VERSION ""

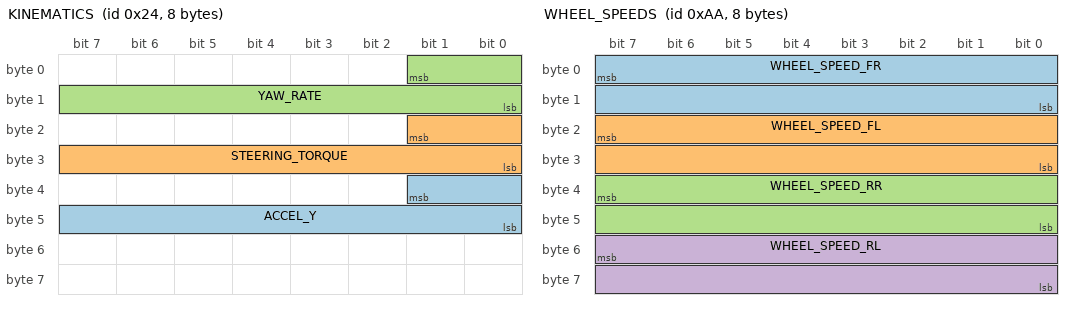
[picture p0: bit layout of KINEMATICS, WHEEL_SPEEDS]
BO_ 36 KINEMATICS: 8 XXX
 SG_ ACCEL_Y : 33|10@0+ (1,-512) [0|65535] "" XXX
 SG_ STEERING_TORQUE : 17|10@0+ (1,-512) [0|65535] "" XXX
 SG_ YAW_RATE : 1|10@0+ (1,-512) [0|65535] "" XXX

BO_ 166 BRAKE: 8 XXX
 SG_ BRAKE_AMOUNT : 7|8@0+ (1,0) [0|255] "" XXX
 SG_ BRAKE_PEDAL : 23|8@0+ (1,0) [0|255] "" XXX

BO_ 170 WHEEL_SPEEDS: 8 XXX
 SG_ WHEEL_SPEED_FR : 7|16@0+ (0.0062,-67.67) [0|250] "mph" XXX
 SG_ WHEEL_SPEED_FL : 23|16@0+ (0.0062,-67.67) [0|250] "mph" XXX
 SG_ WHEEL_SPEED_RR : 39|16@0+ (0.0062,-67.67) [0|250] "mph" XXX
 SG_ WHEEL_SPEED_RL : 55|16@0+ (0.0062,-67.67) [0|250] "mph" XXX

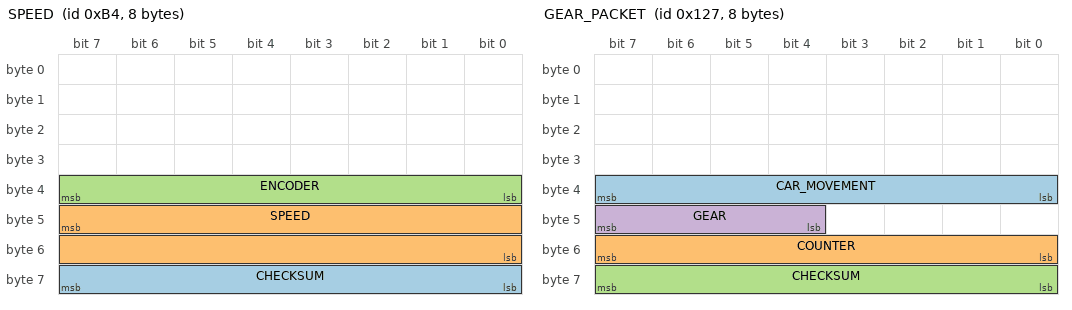
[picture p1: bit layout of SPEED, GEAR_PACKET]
BO_ 180 SPEED: 8 XXX
 SG_ CHECKSUM : 63|8@0+ (1,0) [0|255] "" XXX
 SG_ SPEED : 47|16@0+ (0.0062,0) [0|115] "mph" XXX
 SG_ ENCODER : 39|8@0+ (1,0) [0|255] "" XXX

BO_ 295 GEAR_PACKET: 8 XXX
 SG_ CAR_MOVEMENT : 39|8@0- (1,0) [0|255] "" XXX
 SG_ COUNTER : 55|8@0+ (1,0) [0|255] "" XXX
 SG_ CHECKSUM : 63|8@0+ (1,0) [0|255] "" XXX
 SG_ GEAR : 47|4@0+ (1,0) [0|15] "" XXX

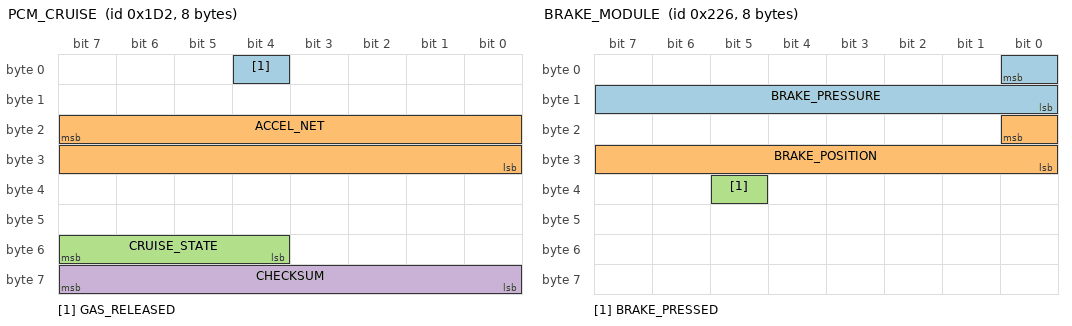
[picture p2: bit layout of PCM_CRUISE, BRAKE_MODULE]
BO_ 466 PCM_CRUISE: 8 XXX
 SG_ GAS_RELEASED : 4|1@0+ (1,0) [0|1] "" XXX
 SG_ ACCEL_NET : 23|16@0- (0.001,0) [-20|20] "m/s2" XXX
 SG_ CRUISE_STATE : 55|4@0+ (1,0) [0|15] "" XXX
 SG_ CHECKSUM : 63|8@0+ (1,0) [0|255] "" XXX

BO_ 550 BRAKE_MODULE: 8 XXX
 SG_ BRAKE_PRESSURE : 0|9@0+ (1,0) [0|511] "" XXX
 SG_ BRAKE_POSITION : 16|9@0+ (1,0) [0|511] "" XXX
 SG_ BRAKE_PRESSED : 37|1@0+ (1,0) [0|1] "" XXX

BO_ 552 ACCELEROMETER: 8 XXX
 SG_ ACCEL_Z : 22|15@0- (1,0) [0|32767] "" XXX
 SG_ ACCEL_X : 6|15@0- (0.001,0) [-20|20] "m/s2" XXX

BO_ 560 BRAKE_MODULE2: 8 XXX
 SG_ BRAKE_LIGHTS : 26|1@0+ (1,0) [0|1] "" XXX

BO_ 581 GAS_PEDAL: 8 XXX
 SG_ GAS_PEDAL : 23|8@0+ (0.005,0) [0|1] "" XXX

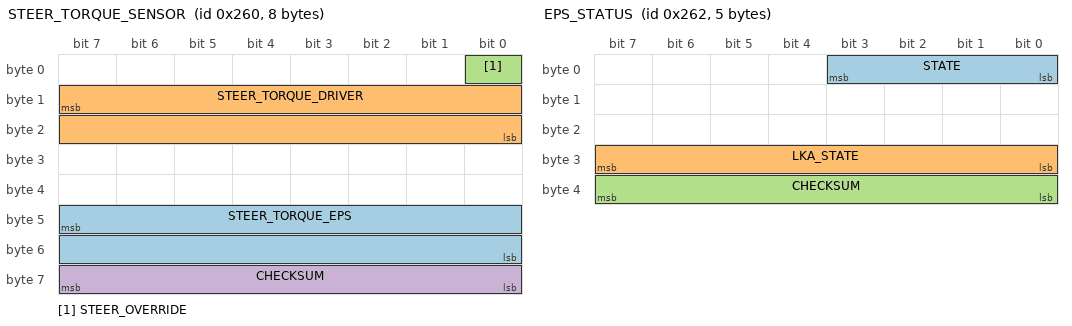
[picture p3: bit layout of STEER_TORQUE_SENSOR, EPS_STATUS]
BO_ 608 STEER_TORQUE_SENSOR: 8 XXX
 SG_ STEER_TORQUE_EPS : 47|16@0- (0.66,0) [-20000|20000] "" XXX
 SG_ STEER_TORQUE_DRIVER : 15|16@0- (1,0) [-32768|32767] "" XXX
 SG_ STEER_OVERRIDE : 0|1@0+ (1,0) [0|1] "" XXX
 SG_ CHECKSUM : 63|8@0+ (1,0) [0|255] "" XXX

BO_ 610 EPS_STATUS: 5 EPS
 SG_ STATE : 3|4@0+ (1,0) [0|15] "" XXX
 SG_ LKA_STATE : 31|8@0+ (1,0) [0|255] "" XXX
 SG_ CHECKSUM : 39|8@0+ (1,0) [0|255] "" XXX

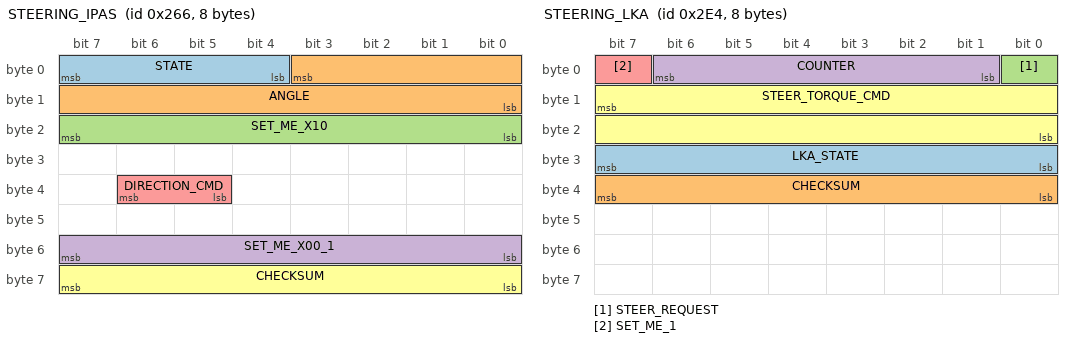
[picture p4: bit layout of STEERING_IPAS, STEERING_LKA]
BO_ 614 STEERING_IPAS: 8 IPAS
 SG_ STATE : 7|4@0+ (1,0) [0|15] "" XXX
 SG_ ANGLE : 3|12@0- (1,0) [0|16777215] "" XXX
 SG_ SET_ME_X10 : 23|8@0+ (1,0) [0|255] "" XXX
 SG_ SET_ME_X00_1 : 55|8@0+ (1,0) [0|255] "" XXX
 SG_ DIRECTION_CMD : 38|2@0+ (1,0) [0|3] "" XXX
 SG_ CHECKSUM : 63|8@0+ (1,0) [0|255] "" XXX

BO_ 643 PRE_COLLISION: 8 XXX

BO_ 740 STEERING_LKA: 8 XXX
 SG_ LKA_STATE : 31|8@0+ (1,0) [0|255] "" XXX
 SG_ CHECKSUM : 39|8@0+ (1,0) [0|255] "" XXX
 SG_ STEER_REQUEST : 0|1@0+ (1,0) [0|1] "" XXX
 SG_ COUNTER : 6|6@0+ (1,0) [0|63] "" XXX
 SG_ SET_ME_1 : 7|1@0+ (1,0) [0|1] "" XXX
 SG_ STEER_TORQUE_CMD : 15|16@0- (1,0) [0|65535] "" XXX

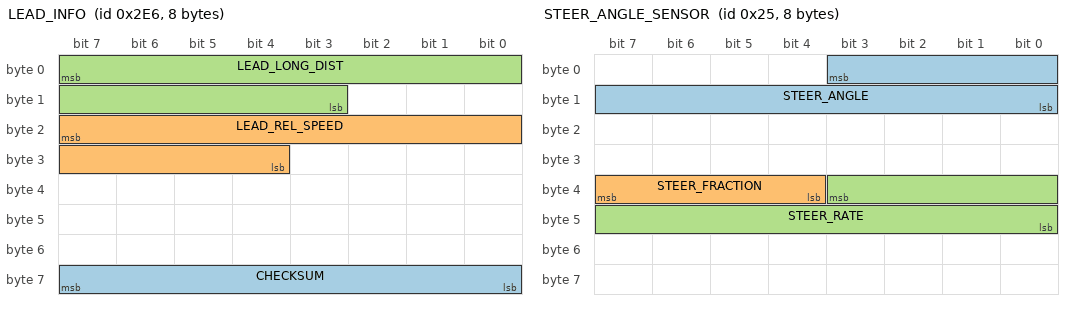
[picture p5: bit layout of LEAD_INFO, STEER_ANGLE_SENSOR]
BO_ 742 LEAD_INFO: 8 DSU
 SG_ CHECKSUM : 63|8@0+ (1,0) [0|255] "" HCU
 SG_ LEAD_REL_SPEED : 23|12@0- (0.025,0) [-100|100] "m/s" HCU
 SG_ LEAD_LONG_DIST : 7|13@0+ (0.05,0) [0|300] "m" HCU

BO_ 835 ACC_CONTROL: 8 DSU
 SG_ ACCEL_CMD : 7|16@0- (0.001,0) [-20|20] "m/s2" HCU

BO_ 1556 STEERING_LEVERS: 8 XXX
 SG_ TURN_SIGNALS : 29|2@0+ (1,0) [0|3] "" XXX

BO_ 37 STEER_ANGLE_SENSOR: 8 XXX
 SG_ STEER_ANGLE : 3|12@0- (1.5,0) [-500|500] "deg" XXX
 SG_ STEER_FRACTION : 39|4@0- (0.1,0) [-0.7|0.7] "deg" XXX
 SG_ STEER_RATE : 35|12@0- (1,0) [-2000|2000] "deg/s" XXX

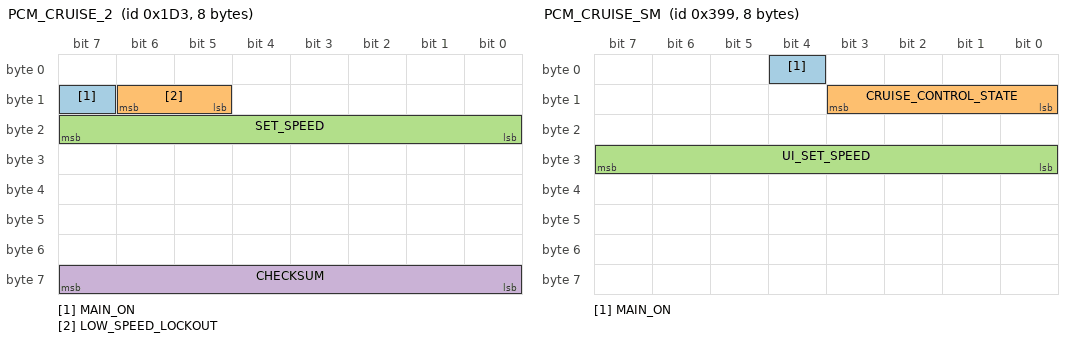
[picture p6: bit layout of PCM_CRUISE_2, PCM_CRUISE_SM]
BO_ 467 PCM_CRUISE_2: 8 XXX
 SG_ MAIN_ON : 15|1@0+ (1,0) [0|1] "" XXX
 SG_ LOW_SPEED_LOCKOUT : 14|2@0+ (1,0) [0|3] "kph" XXX
 SG_ SET_SPEED : 23|8@0+ (1,0) [0|255] "kph" XXX
 SG_ CHECKSUM : 63|8@0+ (1,0) [0|255] "" XXX

BO_ 921 PCM_CRUISE_SM: 8 XXX
 SG_ MAIN_ON : 4|1@0+ (1,0) [0|1] "" XXX
 SG_ CRUISE_CONTROL_STATE : 11|4@0+ (1,0) [0|15] "" XXX
 SG_ UI_SET_SPEED : 31|8@0+ (1,0) [0|255] "" XXX

BO_ 951 ESP_CONTROL: 8 ESP
 SG_ TC_DISABLED : 13|1@0+ (1,0) [0|1] "" XXX

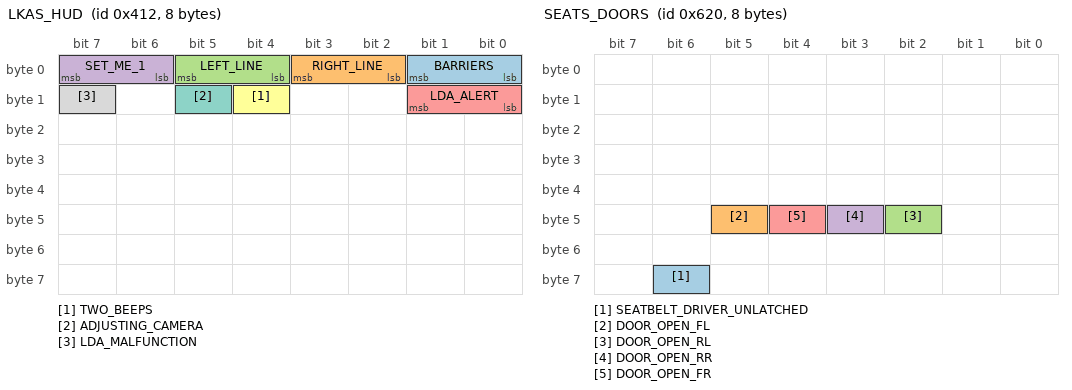
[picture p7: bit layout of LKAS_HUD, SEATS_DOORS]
BO_ 1042 LKAS_HUD: 8 XXX
 SG_ BARRIERS : 1|2@0+ (1,0) [0|3] "" XXX
 SG_ RIGHT_LINE : 3|2@0+ (1,0) [0|3] "" XXX
 SG_ LEFT_LINE : 5|2@0+ (1,0) [0|3] "" XXX
 SG_ SET_ME_1 : 7|2@0+ (1,0) [0|3] "" XXX
 SG_ LDA_ALERT : 9|2@0+ (1,0) [0|3] "" XXX
 SG_ TWO_BEEPS : 12|1@0+ (1,0) [0|1] "" XXX
 SG_ ADJUSTING_CAMERA : 13|1@0+ (1,0) [0|1] "" XXX
 SG_ LDA_MALFUNCTION : 15|1@0+ (1,0) [0|1] "" XXX

BO_ 1553 UI_SEETING: 8 XXX
 SG_ UNITS : 26|2@0+ (1,0) [0|3] "" XXX

BO_ 1568 SEATS_DOORS: 8 XXX
 SG_ SEATBELT_DRIVER_UNLATCHED : 62|1@0+ (1,0) [0|1] "" XXX
 SG_ DOOR_OPEN_FL : 45|1@0+ (1,0) [0|1] "" XXX
 SG_ DOOR_OPEN_RL : 42|1@0+ (1,0) [0|1] "" XXX
 SG_ DOOR_OPEN_RR : 43|1@0+ (1,0) [0|1] "" XXX
 SG_ DOOR_OPEN_FR : 44|1@0+ (1,0) [0|1] "" XXX

BO_ 452 POWERTRAIN: 8 XXX
 SG_ ENGINE_RPM : 7|16@0+ (1,0) [0|65535] "rpm" XXX
 SG_ CHECKSUM : 63|8@0+ (1,0) [0|255] "" XXX

VAL_ 262 DI_torqueDriver -4096 "SNA" ;
VAL_ 262 DI_torqueMotor -4096 "SNA" ;
VAL_ 262 DI_soptState 7 "SOPT_TEST_SNA" 4 "SOPT_TEST_NOT_RUN" 3 "SOPT_TEST_PASSED" 2 "SOPT_TEST_FAILED" 1 "SOPT_TEST_IN_PROGRESS" 0 "SOPT_PRE_TEST" ;
VAL_ 262 DI_motorRPM -32768 "SNA" ;
VAL_ 262 DI_pedalPos 255 "SNA" ;
VAL_ 278 DI_torqueEstimate -2048 "SNA" ;
VAL_ 278 DI_gear 7 "DI_GEAR_SNA" 4 "DI_GEAR_D" 3 "DI_GEAR_N" 2 "DI_GEAR_R" 1 "DI_GEAR_P" 0 "DI_GEAR_INVALID" ;
VAL_ 278 DI_brakePedal 1 "Applied" 0 "Not_applied" ;
VAL_ 278 DI_vehicleSpeed 4095 "SNA" ;
VAL_ 278 DI_gearRequest 7 "DI_GEAR_SNA" 4 "DI_GEAR_D" 3 "DI_GEAR_N" 2 "DI_GEAR_R" 1 "DI_GEAR_P" 0 "DI_GEAR_INVALID" ;
VAL_ 278 DI_torqueInterfaceFailure 1 "TORQUE_INTERFACE_FAILED" 0 "TORQUE_INTERFACE_NORMAL" ;
VAL_ 278 DI_brakePedalState 3 "SNA" 2 "INVALID" 1 "ON" 0 "OFF" ;
VAL_ 278 DI_epbParkRequest 1 "Park_requested" 0 "No_request" ;
VAL_ 278 DI_epbInterfaceReady 1 "EPB_INTERFACE_READY" 0 "EPB_INTERFACE_NOT_READY" ;
VAL_ 504 driverBrakeStatus 2 "APPLIED" 1 "NOT_APPLIED" ;
VAL_ 568 SpdCtrlLvr_Stat 32 "DN_1ST" 16 "UP_1ST" 8 "DN_2ND" 4 "UP_2ND" 2 "RWD" 1 "FWD" 0 "IDLE" ;
VAL_ 568 DTR_Dist_Rq 255 "SNA" 200 "ACC_DIST_7" 166 "ACC_DIST_6" 133 "ACC_DIST_5" 100 "ACC_DIST_4" 66 "ACC_DIST_3" 33 "ACC_DIST_2" 0 "ACC_DIST_1" ;
VAL_ 568 TurnIndLvr_Stat 3 "SNA" 2 "RIGHT" 1 "LEFT" 0 "IDLE" ;
VAL_ 568 HiBmLvr_Stat 3 "SNA" 2 "HIBM_FLSH_ON_PSD" 1 "HIBM_ON_PSD" 0 "IDLE" ;
VAL_ 568 WprWashSw_Psd 3 "SNA" 2 "WASH" 1 "TIPWIPE" 0 "NPSD" ;
VAL_ 568 WprWash_R_Sw_Posn_V2 3 "SNA" 2 "WASH" 1 "INTERVAL" 0 "OFF" ;
VAL_ 568 StW_Lvr_Stat 4 "STW_BACK" 3 "STW_FWD" 2 "STW_DOWN" 1 "STW_UP" 0 "NPSD" ;
VAL_ 568 StW_Cond_Psd 3 "SNA" 2 "DOWN" 1 "UP" 0 "NPSD" ;
VAL_ 568 HrnSw_Psd 3 "SNA" 2 "NDEF2" 1 "PSD" 0 "NPSD" ;
VAL_ 568 StW_Sw00_Psd 1 "PRESSED" 0 "NOT_PRESSED_SNA" ;
VAL_ 568 StW_Sw01_Psd 1 "PRESSED" 0 "NOT_PRESSED_SNA" ;
VAL_ 568 StW_Sw03_Psd 1 "PRESSED" 0 "NOT_PRESSED_SNA" ;
VAL_ 568 StW_Sw04_Psd 1 "PRESSED" 0 "NOT_PRESSED_SNA" ;
VAL_ 568 WprSw6Posn 7 "SNA" 6 "STAGE2" 5 "STAGE1" 4 "INTERVAL4" 3 "INTERVAL3" 2 "INTERVAL2" 1 "INTERVAL1" 0 "OFF" ;
VAL_ 598 DI_aebState 2 "ENABLED" 4 "FAULT" 7 "SNA" 1 "STANDBY" 3 "STANDSTILL" 0 "UNAVAILABLE" ;
VAL_ 598 DI_analogSpeed 4095 "SNA" ;
VAL_ 598 DI_cruiseState 2 "ENABLED" 5 "FAULT" 0 "OFF" 4 "OVERRIDE" 7 "PRE_CANCEL" 6 "PRE_FAULT" 1 "STANDBY" 3 "STANDSTILL" ;
VAL_ 598 DI_digitalSpeed 255 "SNA" ;
VAL_ 598 DI_immobilizerState 2 "AUTHENTICATING" 3 "DISARMED" 6 "FAULT" 4 "IDLE" 0 "INIT_SNA" 1 "REQUEST" 5 "RESET" ;
VAL_ 598 DI_speedUnits 1 "KPH" 0 "MPH" ;
VAL_ 598 DI_state 3 "ABORT" 4 "ENABLE" 2 "FAULT" 1 "STANDBY" 0 "UNAVAILABLE" ;
VAL_ 598 DI_systemState 3 "ABORT" 4 "ENABLE" 2 "FAULT" 1 "STANDBY" 0 "UNAVAILABLE" ;
VAL_ 598 DI_vehicleHoldState 2 "BLEND_IN" 4 "BLEND_OUT" 6 "FAULT" 7 "INIT" 5 "PARK" 1 "STANDBY" 3 "STANDSTILL" 0 "UNAVAILABLE" ;
VAL_ 703 DAS_setSpeed 4095 "SNA" ;
VAL_ 703 DAS_accState 15 "FAULT_SNA" 13 "ACC_CANCEL_GENERIC_SILENT" 11 "APC_SELFPARK_START" 10 "APC_UNPARK_COMPLETE" 9 "APC_PAUSE" 8 "APC_ABORT" 7 "APC_COMPLETE" 6 "APC_FORWARD" 5 "APC_BACKWARD" 4 "ACC_ON" 3 "ACC_HOLD" 0 "ACC_CANCEL_GENERIC" ;
VAL_ 703 DAS_aebEvent 3 "AEB_SNA" 2 "AEB_FAULT" 1 "AEB_ACTIVE" 0 "AEB_NOT_ACTIVE" ;
VAL_ 703 DAS_jerkMin 511 "SNA" ;
VAL_ 703 DAS_jerkMax 255 "SNA" ;
VAL_ 703 DAS_accelMin 511 "SNA" ;
